AUTOSAR XML (schema 00046)
package /ComponentTypes
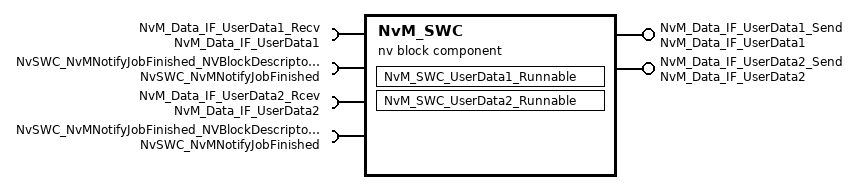
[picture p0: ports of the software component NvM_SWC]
  nv block sw component type NvM_SWC
    provide port NvM_Data_IF_UserData1_Send: nv-provide-com-spec{ram-block-init-value=10 x 0, rom-block-init-value=10 x 0, variable=Element_UserData1}, provided-interface=NvM_Data_IF_UserData1
    require port NvM_Data_IF_UserData1_Recv: nv-require-com-spec{init-value=10 x 0, variable=Element_UserData1}, required-interface=NvM_Data_IF_UserData1
    require port NvSWC_NvMNotifyJobFinished_NVBlockDescriptor_UserData1: client-com-spec=JobFinished, required-interface=NvSWC_NvMNotifyJobFinished
    provide port NvM_Data_IF_UserData2_Send: nv-provide-com-spec{ram-block-init-value=32 x 0, rom-block-init-value=32 x 0, variable=Element_UserData2}, provided-interface=NvM_Data_IF_UserData2
    require port NvM_Data_IF_UserData2_Rcev: nv-require-com-spec{init-value=32 x 0, variable=Element_UserData2}, required-interface=NvM_Data_IF_UserData2
    require port NvSWC_NvMNotifyJobFinished_NVBlockDescriptor_UserData2: client-com-spec=JobFinished, required-interface=NvSWC_NvMNotifyJobFinished
    behavior NvM_SWC_InternalBehavior
      data received event DRT_NvM_SWC_Runnable_NvM_Data_IF_UserData1_Recv_Element_UserData1: start-on-event=NvM_SWC_UserData1_Runnable, data=NvM_Data_IF_UserData1_Recv.Element_UserData1
      data received event DRT_NvM_SWC_UserData2_Runnable_NvM_Data_IF_UserData2_Rcev_Element_UserData2: start-on-event=NvM_SWC_UserData2_Runnable, data=NvM_Data_IF_UserData2_Rcev.Element_UserData2
      runnable NvM_SWC_UserData1_Runnable
      runnable NvM_SWC_UserData2_Runnable
    nv block descriptor NVBlockDescriptor_UserData1: client-server-ports=role-based-port-assignment={port-prototype=NvSWC_NvMNotifyJobFinished_NVBlockDescriptor_UserData1, role=NvMNotifyJobFinished}
      nv-block-data-mappings:
        nv-ram-block-element=RAM_NVBlockDescriptor_UserData1, written-nv-data=NvM_Data_IF_UserData1_Recv.Element_UserData1
        nv-ram-block-element=RAM_NVBlockDescriptor_UserData1, read-nv-data=NvM_Data_IF_UserData1_Send.Element_UserData1
      nv block needs NVNeed_NVBlockDescriptor_UserData1:
        calc-ram-block-crc=false
        check-static-block-id=false
        n-data-sets=1
        n-rom-blocks=1
        ram-block-status-control=API
        readonly=false
        reliability=ERROR-DETECTION
        resistant-to-changed-sw=true
        restore-at-start=true
        store-at-shutdown=true
        store-cyclic=false
        store-emergency=false
        store-immediate=false
        use-auto-validation-at-shut-down=false
        use-crc-comp-mechanism=false
        write-only-once=false
        write-verification=false
        writing-frequency=1000000
      ram block RAM_NVBlockDescriptor_UserData1: type=NvM_Array10Bytes, init-value=10 x 0
      rom block ROM_NVBlockDescriptor_UserData1: sw-calibration-access=READ-ONLY, type=NvM_Array10Bytes, init-value=10 x 0
    nv block descriptor NVBlockDescriptor_UserData2: client-server-ports=role-based-port-assignment={port-prototype=NvSWC_NvMNotifyJobFinished_NVBlockDescriptor_UserData2, role=NvMNotifyJobFinished}
      nv-block-data-mappings:
        nv-ram-block-element=RAM_NVBlockDescriptor_UserData2, written-nv-data=NvM_Data_IF_UserData2_Rcev.Element_UserData2
        nv-ram-block-element=RAM_NVBlockDescriptor_UserData2, read-nv-data=NvM_Data_IF_UserData2_Send.Element_UserData2
      nv block needs NVNeed_NVBlockDescriptor_UserData2:
        calc-ram-block-crc=false
        check-static-block-id=false
        n-data-sets=1
        n-rom-blocks=1
        ram-block-status-control=API
        readonly=false
        reliability=ERROR-DETECTION
        resistant-to-changed-sw=true
        restore-at-start=true
        store-at-shutdown=true
        store-cyclic=false
        store-emergency=false
        store-immediate=false
        use-auto-validation-at-shut-down=false
        use-crc-comp-mechanism=false
        write-only-once=false
        write-verification=false
        writing-frequency=100000
      ram block RAM_NVBlockDescriptor_UserData2: type=NvM_Array32Bytes, init-value=32 x 0
      rom block ROM_NVBlockDescriptor_UserData2: sw-calibration-access=READ-ONLY, type=NvM_Array32Bytes, init-value=32 x 0
  swc implementation NvM_SWC_Implementation: behavior=NvM_SWC_InternalBehavior
